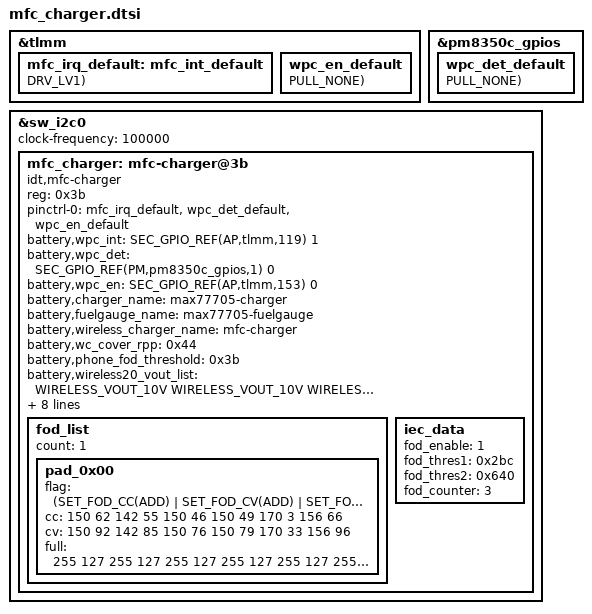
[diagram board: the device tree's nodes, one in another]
#include <dt-bindings/battery/sec-battery.h>

&tlmm {
	mfc_irq_default: mfc_int_default {
			 GPIO_CONFIG_PUD_DRV(AP,tlmm,119, FUNC_INPUT_WAKEUP, PULL_NONE, DRV_LV1);
		 };
};

&pm8350c_gpios {
	wpc_det_default: wpc_det_default {
			 GPIO_CONFIG_PUD(PM,pm8350c_gpios,1, FUNC_INPUT_WAKEUP, PULL_NONE);
		 };
};

&tlmm {
	wpc_en_default: wpc_en_default {
			 GPIO_CONFIG_PUD(AP,tlmm,153, FUNC_OUTPUT_LOW, PULL_NONE);
		 };
};

#define FOD_FLAG_NONE			0
#define FOD_FLAG_ADD			1
#define FOD_FLAG_USE_CC			2
#define FOD_FLAG_USE_DEFAULT	3
#define SET_FOD_CC(_flag)		(FOD_FLAG_ ##_flag)
#define SET_FOD_CV(_flag)		(FOD_FLAG_ ##_flag << 4)
#define SET_FOD_FULL(_flag)		(FOD_FLAG_ ##_flag << 8)

&sw_i2c0 {
	#address-cells = <1>;
	#size-cells = <0>;
	status = "okay";
	clock-frequency = <100000>;

	mfc_charger: mfc-charger@3b {
		compatible = "idt,mfc-charger";
		reg = <0x3b>;
		status = "okay";

		pinctrl-names = "default";
		pinctrl-0 = <&mfc_irq_default &wpc_det_default &wpc_en_default>;

		battery,wpc_int = <SEC_GPIO_REF(AP,tlmm,119) 1>; /* MFC_AP_INT */
		battery,wpc_det = <SEC_GPIO_REF(PM,pm8350c_gpios,1) 0>; /* WPC_DET */
#if 0
		battery,mst_pwr_en = <SEC_GPIO_REF(${mst_pwr_en_gpio}) 0>; /* MST_PWR_EN */
#endif
		battery,wpc_en = <SEC_GPIO_REF(AP,tlmm,153) 0>; /* WPC_EN */

		battery,charger_name = "max77705-charger";
		battery,fuelgauge_name = "max77705-fuelgauge";
		battery,wireless_charger_name = "mfc-charger";
		battery,wc_cover_rpp = <0x44>;
		battery,phone_fod_threshold = <0x3b>;
		battery,wireless20_vout_list = <WIRELESS_VOUT_11V WIRELESS_VOUT_11V WIRELESS_VOUT_11V>;
		battery,wireless20_vrect_list = <MFC_AFC_CONF_12V_TX MFC_AFC_CONF_12_5V_TX MFC_AFC_CONF_12_5V_TX>;
		battery,wireless20_max_power_list = <SEC_WIRELESS_RX_POWER_12W SEC_WIRELESS_RX_POWER_15W SEC_WIRELESS_RX_POWER_15W>;
		battery,oc_fod1 = <1100>;

		fod_list {
			count = <1>;

			pad_0x00 { /* DEFAULT */
				flag = <(SET_FOD_CC(ADD) | SET_FOD_CV(ADD) | SET_FOD_FULL(ADD))>;
				cc = <150 64 142 53 150 38 150 34 155 18 156 17>;
				cv = <150 94 142 83 150 68 150 64 155 48 156 47>;
				full = <255 127 255 127 255 127 255 127 255 127 255 127>;
			};
		};
	};
};

/* /home/dpi/qb5_8814/workspace/P4_1716/android/kernel/kmodule/battery/wireless/mfc_charger_gki/mfc_charger.b2q.dtsi */
&mfc_charger {
	battery,wireless20_vout_list = <WIRELESS_VOUT_10V WIRELESS_VOUT_10V WIRELESS_VOUT_10V>;
	battery,wireless20_vrect_list = <MFC_AFC_CONF_12V_TX MFC_AFC_CONF_12_5V_TX MFC_AFC_CONF_12_5V_TX>;
	battery,wireless20_max_power_list = <SEC_WIRELESS_RX_POWER_12W SEC_WIRELESS_RX_POWER_15W SEC_WIRELESS_RX_POWER_15W>;
	battery,wpc_vout_ctrl_full = <WIRELESS_VOUT_4_5V_STEP>;
	battery,wpc_headroom_ctrl_full;

	fod_list {
		pad_0x00 { /* DEFAULT */
			cc = <150 62 142 55 150 46 150 49 170 3 156 66>;
			cv = <150 92 142 85 150 76 150 79 170 33 156 96>;
		};
	};
	iec_data {
		fod_enable = <1>;
		fod_thres1 = <0x2bc>; /* 700mW */
		fod_thres2 = <0x640>; /* 1600mW */
		fod_counter = <3>;
	};
};
